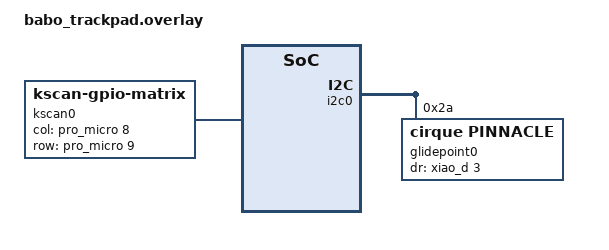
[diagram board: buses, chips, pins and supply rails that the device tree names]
#include <dt-bindings/zmk/matrix_transform.h>

&i2c0 {
	status = "disabled";
    glidepoint0: glidepoint@2a {
		compatible = "cirque,pinnacle";
		reg = <0x2a>;
		status = "disabled";
		dr-gpios = <&xiao_d 3 (GPIO_ACTIVE_HIGH)>;
		sensitivity = "2x";
	};
};

&i2c0 {
    status = "okay";
    glidepoint: glidepoint@2a {
        status = "okay";
    };
};


/ {
    chosen {
        zmk,kscan = &kscan0;
    }

    kscan0: kscan {
        compatible = "zmk,kscan-gpio-matrix";
        wakeup-source;

        diode-direction = "col2row";
    };

    tpad0: tpad0 {
        compatible = "zmk,input-listener";

        device = <&glidepoint>;
        xy-swap;
        scale-multiplier = <7>;
        scale-divisor = <3>;
        // y-invert;
        // x-invert;
    };
};


&kscan0 {
    col-gpios
        = <&pro_micro 8 GPIO_ACTIVE_HIGH>
        ;
    row-gpios
        = <&pro_micro 9 (GPIO_ACTIVE_HIGH | GPIO_PULL_DOWN)>
        ;
};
